AUTOSAR XML (schema 4.0)
standard types defined: float32, float64, sint16, sint32, sint8, uint16, uint32, uint8, void, boolean
package /ImplDataTypes
  4 x impl type, all with category=TYPE_REFERENCE, type-emitter=RTE:
    Impl_SensorPositionType: implementation-data-type=sint32
    Impl_SensorWeightType: implementation-data-type=uint32
    MultiStateBtnType: implementation-data-type=uint8
    StepMotorStepType: implementation-data-type=uint8
package /MappingSets
  data type mapping set MappingSet
package /PortInterfaces/ClientServer
  client server interface CsIf_PositionSensor
    operation Opr_GetPosition
      arg position: type=Impl_SensorPositionType, direction=OUT
  client server interface CsIf_StepMotor
    operation Opr_Move
      arg Arg_step: type=StepMotorStepType, direction=IN
  client server interface CsIf_WeightSensor
    operation GetWeight
      arg weight: type=Impl_SensorWeightType, direction=OUT
package /PortInterfaces/SenderReceiver
  sender receiver interface SrIf_SeatCtrlBtns
    data DE_HeightBtnState: type=MultiStateBtnType
    data DE_InclineBtnState: type=MultiStateBtnType
    data DE_SlideBtnState: type=MultiStateBtnType
  sender receiver interface SrIf_SeatCtrlData
    data DE_Height: type=uint8
    data DE_Incline: type=uint8
    data DE_Slide: type=uint8
package /SoftwareComponents
  10 x swc implementation, all with programming-language=C, sw-version=1.0.0, vendor-id=255:
    Impl_SWC_ECU1: behavior=Ibhv_SWC_ECU1
      code-descriptors:
        code Code: artifact-descriptors=autosar-engineering-object={short-label=SWC.c, category=SWSRC}
      resource consumption ResourceConsumption
    Impl_SWC_HMI: behavior=Ibhv_SWC_HMI
      code-descriptors:
        code Code: artifact-descriptors=autosar-engineering-object={short-label=SWC.c, category=SWSRC}
      resource consumption ResourceConsumption
    Impl_SWC_HeightMotor: behavior=Ibhv_SWC_HeightMotor
      code-descriptors:
        code Code: artifact-descriptors=autosar-engineering-object={short-label=SWC.c, category=SWSRC}
      resource consumption ResourceConsumption
    Impl_SWC_HeightSensor: behavior=Ibhv_SWC_HeightSensor
      code-descriptors:
        code Code: artifact-descriptors=autosar-engineering-object={short-label=SWC.c, category=SWSRC}
      resource consumption ResourceConsumption
    Impl_SWC_InclineMotor: behavior=Ibhv_SWC_InclineMotor
      code-descriptors:
        code Code: artifact-descriptors=autosar-engineering-object={short-label=SWC.c, category=SWSRC}
      resource consumption ResourceConsumption
    Impl_SWC_InclineSensor: behavior=Ibhv_SWC_InclineSensor
      code-descriptors:
        code Code: artifact-descriptors=autosar-engineering-object={short-label=SWC.c, category=SWSRC}
      resource consumption ResourceConsumption
    Impl_SWC_SeatMgr: behavior=Ibhv_SWC_SeatMgr
      code-descriptors:
        code Code: artifact-descriptors=autosar-engineering-object={short-label=SWC.c, category=SWSRC}
      resource consumption ResourceConsumption
    Impl_SWC_SlideMotor: behavior=Ibhv_SWC_SlideMotor
      code-descriptors:
        code Code: artifact-descriptors=autosar-engineering-object={short-label=SWC.c, category=SWSRC}
      resource consumption ResourceConsumption
    Impl_SWC_SlideSensor: behavior=Ibhv_SWC_SlideSensor
      code-descriptors:
        code Code: artifact-descriptors=autosar-engineering-object={short-label=SWC.c, category=SWSRC}
      resource consumption ResourceConsumption
    Impl_SWC_WeightSensor: behavior=Ibhv_SWC_WeightSensor
      code-descriptors:
        code Code: artifact-descriptors=autosar-engineering-object={short-label=SWC.c, category=SWSRC}
      resource consumption ResourceConsumption
  application sw component type SWC_ECU1
    provide port pp_SeatCtrlData: provided-interface=SrIf_SeatCtrlData
    behavior Ibhv_SWC_ECU1: data-type-mapping=MappingSet, handle-termination-and-restart=NO-SUPPORT
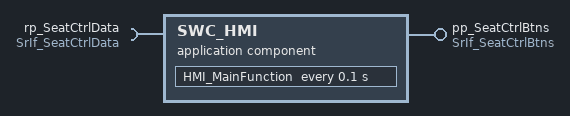
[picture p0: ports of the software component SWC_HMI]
  application sw component type SWC_HMI
    provide port pp_SeatCtrlBtns: provided-interface=SrIf_SeatCtrlBtns
    require port rp_SeatCtrlData: required-interface=SrIf_SeatCtrlData
    behavior Ibhv_SWC_HMI: data-type-mapping=MappingSet, handle-termination-and-restart=NO-SUPPORT
      timing event TE_HMI_MainFunction_100ms: start-on-event=HMI_MainFunction, period=0.1
      runnable HMI_MainFunction
        data-receive-point-by-arguments:
          access DRP_rp_SeatCtrlData_DE_Height: accessed-variable=rp_SeatCtrlData.DE_Height
          access DRP_rp_SeatCtrlData_DE_Incline: accessed-variable=rp_SeatCtrlData.DE_Incline
          access DRP_rp_SeatCtrlData_DE_Slide: accessed-variable=rp_SeatCtrlData.DE_Slide
        data-send-points:
          access DSP_pp_SeatCtrlBtns_DE_HeightBtnState: accessed-variable=pp_SeatCtrlBtns.DE_HeightBtnState
          access DSP_pp_SeatCtrlBtns_DE_InclineBtnState: accessed-variable=pp_SeatCtrlBtns.DE_InclineBtnState
          access DSP_pp_SeatCtrlBtns_DE_SlideBtnState: accessed-variable=pp_SeatCtrlBtns.DE_SlideBtnState
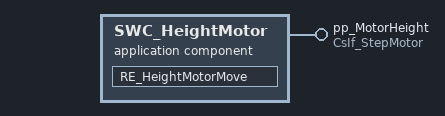
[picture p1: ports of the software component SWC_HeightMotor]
  application sw component type SWC_HeightMotor
    provide port pp_MotorHeight: provided-interface=CsIf_StepMotor
    behavior Ibhv_SWC_HeightMotor: data-type-mapping=MappingSet, handle-termination-and-restart=NO-SUPPORT
      operation invoked event OIE_pp_MotorHeight_Opr_Move: start-on-event=RE_HeightMotorMove, operation=pp_MotorHeight.Opr_Move
      runnable RE_HeightMotorMove
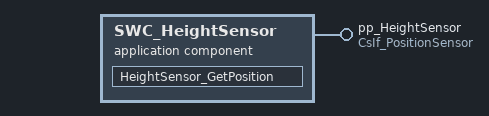
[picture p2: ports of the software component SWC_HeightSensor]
  application sw component type SWC_HeightSensor
    provide port pp_HeightSensor: provided-interface=CsIf_PositionSensor
    behavior Ibhv_SWC_HeightSensor: data-type-mapping=MappingSet, handle-termination-and-restart=NO-SUPPORT
      operation invoked event OIE_pp_HeightSensor_Opr_GetPosition: start-on-event=HeightSensor_GetPosition, operation=pp_HeightSensor.Opr_GetPosition
      runnable HeightSensor_GetPosition
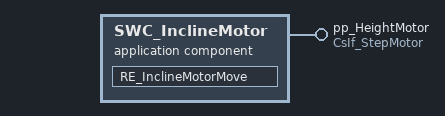
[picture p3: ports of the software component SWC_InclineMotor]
  application sw component type SWC_InclineMotor
    provide port pp_HeightMotor: provided-interface=CsIf_StepMotor
    behavior Ibhv_SWC_InclineMotor: data-type-mapping=MappingSet, handle-termination-and-restart=NO-SUPPORT
      operation invoked event OIE_pp_HeightMotor_Opr_Move: start-on-event=RE_InclineMotorMove, operation=pp_HeightMotor.Opr_Move
      runnable RE_InclineMotorMove
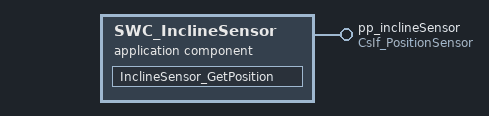
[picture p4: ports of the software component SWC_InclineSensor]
  application sw component type SWC_InclineSensor
    provide port pp_inclineSensor: provided-interface=CsIf_PositionSensor
    behavior Ibhv_SWC_InclineSensor: data-type-mapping=MappingSet, handle-termination-and-restart=NO-SUPPORT
      operation invoked event OIE_pp_inclineSensor_Opr_GetPosition: start-on-event=InclineSensor_GetPosition, operation=pp_inclineSensor.Opr_GetPosition
      runnable InclineSensor_GetPosition
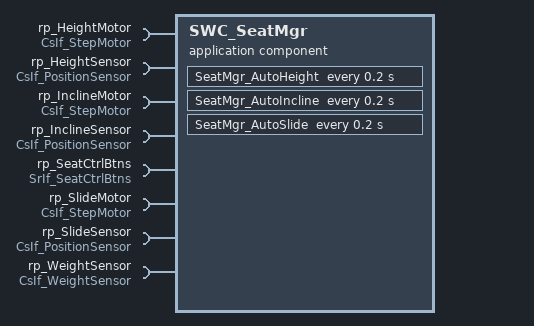
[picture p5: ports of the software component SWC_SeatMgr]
  application sw component type SWC_SeatMgr
    8 x require port:
      rp_HeightMotor: required-interface=CsIf_StepMotor
      rp_HeightSensor: required-interface=CsIf_PositionSensor
      rp_InclineMotor: required-interface=CsIf_StepMotor
      rp_InclineSensor: required-interface=CsIf_PositionSensor
      rp_SeatCtrlBtns: required-interface=SrIf_SeatCtrlBtns
      rp_SlideMotor: required-interface=CsIf_StepMotor
      rp_SlideSensor: required-interface=CsIf_PositionSensor
      rp_WeightSensor: required-interface=CsIf_WeightSensor
    behavior Ibhv_SWC_SeatMgr: data-type-mapping=MappingSet, handle-termination-and-restart=NO-SUPPORT
      data received event DRE_rp_SeatCtrlBtns_DE_HeightBtnState: start-on-event=SeatMgr_SetHeight, data=rp_SeatCtrlBtns.DE_HeightBtnState
      data received event DRE_rp_SeatCtrlBtns_DE_InclineBtnState: start-on-event=SeatMgr_SetIncline, data=rp_SeatCtrlBtns.DE_InclineBtnState
      data received event DRE_rp_SeatCtrlBtns_DE_SlideBtnState: start-on-event=SeatMgr_SetSlide, data=rp_SeatCtrlBtns.DE_SlideBtnState
      timing event TE_SeatMgr_AutoHeight_200ms: start-on-event=SeatMgr_AutoHeight, period=0.2
      timing event TE_SeatMgr_AutoIncline_200ms: start-on-event=SeatMgr_AutoIncline, period=0.2
      timing event TE_SeatMgr_AutoSlide_200ms: start-on-event=SeatMgr_AutoSlide, period=0.2
      6 x runnable:
        SeatMgr_AutoHeight
          sync call SCP_rp_HeightMotor_Opr_Move: operation=rp_HeightMotor.Opr_Move, timeout=0.0
          sync call SCP_rp_HeightSensor_Opr_GetPosition: operation=rp_HeightSensor.Opr_GetPosition, timeout=0.0
          sync call SCP_rp_WeightSensor_GetWeight: operation=rp_WeightSensor.GetWeight, timeout=0.0
        SeatMgr_AutoIncline
          sync call SCP_rp_InclineMotor_Opr_Move: operation=rp_InclineMotor.Opr_Move, timeout=0.0
          sync call SCP_rp_InclineSensor_Opr_GetPosition: operation=rp_InclineSensor.Opr_GetPosition, timeout=0.0
          sync call SCP_rp_WeightSensor_GetWeight: operation=rp_WeightSensor.GetWeight, timeout=0.0
        SeatMgr_AutoSlide
          sync call SCP_rp_SlideMotor_Opr_Move: operation=rp_SlideMotor.Opr_Move, timeout=0.0
          sync call SCP_rp_SlideSensor_Opr_GetPosition: operation=rp_SlideSensor.Opr_GetPosition, timeout=0.0
          sync call SCP_rp_WeightSensor_GetWeight: operation=rp_WeightSensor.GetWeight, timeout=0.0
        SeatMgr_SetHeight
          data-receive-point-by-arguments:
            access DRP_rp_SeatCtrlBtns_DE_HeightBtnState: accessed-variable=rp_SeatCtrlBtns.DE_HeightBtnState
          sync call SCP_rp_HeightMotor_Opr_Move: operation=rp_HeightMotor.Opr_Move, timeout=0.0
        SeatMgr_SetIncline
          data-receive-point-by-arguments:
            access DRP_rp_SeatCtrlBtns_DE_InclineBtnState: accessed-variable=rp_SeatCtrlBtns.DE_InclineBtnState
          sync call SCP_rp_InclineMotor_Opr_Move: operation=rp_InclineMotor.Opr_Move, timeout=0.0
        SeatMgr_SetSlide
          data-receive-point-by-arguments:
            access DRP_rp_SeatCtrlBtns_DE_SlideBtnState: accessed-variable=rp_SeatCtrlBtns.DE_SlideBtnState
          sync call SCP_rp_SlideMotor_Opr_Move: operation=rp_SlideMotor.Opr_Move, timeout=0.0
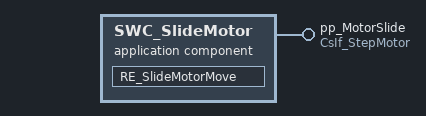
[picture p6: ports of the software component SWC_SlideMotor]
  application sw component type SWC_SlideMotor
    provide port pp_MotorSlide: provided-interface=CsIf_StepMotor
    behavior Ibhv_SWC_SlideMotor: data-type-mapping=MappingSet, handle-termination-and-restart=NO-SUPPORT
      operation invoked event OIE_pp_MotorSlide_Opr_Move: start-on-event=RE_SlideMotorMove, operation=pp_MotorSlide.Opr_Move
      runnable RE_SlideMotorMove
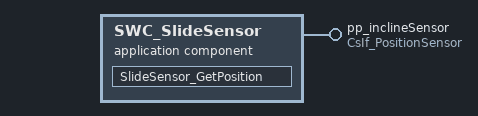
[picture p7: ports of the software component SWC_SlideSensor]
  application sw component type SWC_SlideSensor
    provide port pp_inclineSensor: provided-interface=CsIf_PositionSensor
    behavior Ibhv_SWC_SlideSensor: data-type-mapping=MappingSet, handle-termination-and-restart=NO-SUPPORT
      operation invoked event OIE_pp_inclineSensor_Opr_GetPosition: start-on-event=SlideSensor_GetPosition, operation=pp_inclineSensor.Opr_GetPosition
      runnable SlideSensor_GetPosition
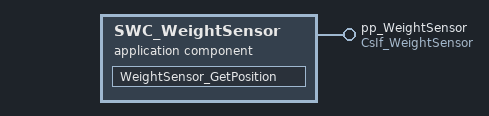
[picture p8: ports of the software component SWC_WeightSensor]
  application sw component type SWC_WeightSensor
    provide port pp_WeightSensor: provided-interface=CsIf_WeightSensor
    behavior Ibhv_SWC_WeightSensor: data-type-mapping=MappingSet, handle-termination-and-restart=NO-SUPPORT
      operation invoked event OIE_pp_WeightSensor_GetWeight: start-on-event=WeightSensor_GetPosition, operation=pp_WeightSensor.GetWeight
      runnable WeightSensor_GetPosition
package /Compositions
  composition sw component type SeatCtrlComposition
    component SWC_HMI: type=SWC_HMI
    component SWC_SeatMgr: type=SWC_SeatMgr
